# GD32H71x_72x register map
File version: 1.0
CPU: CM7 r1p2, little endian, MPU, FPU, 4 interrupt priority bits
Registers are 32-bit, read-write, reset 0x0 unless marked. A register's access mark holds for its fields unless they carry their own. Offsets are from the block's base; [hi:lo] are bit positions.

## PMU — Power management unit
Base 0x58005800
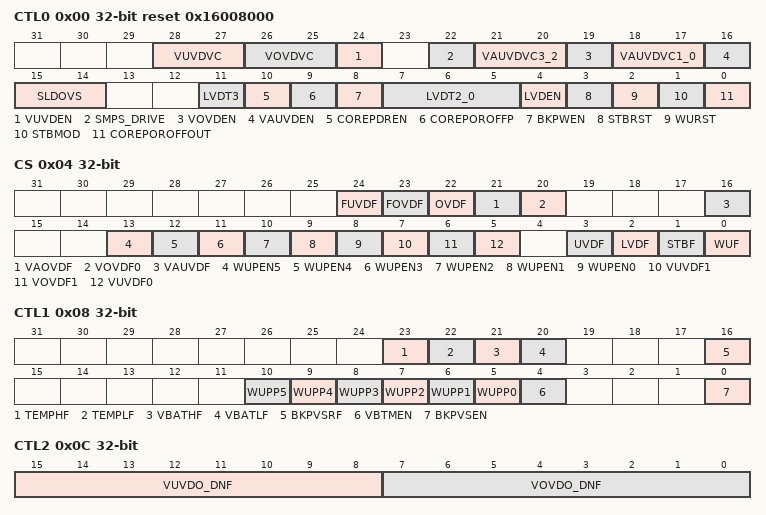
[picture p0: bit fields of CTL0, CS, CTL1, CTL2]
0x00 CTL0 reset 0x16008000 — Control register 0
  [28:27] VUVDVC — VCORE under voltage detector voltage level configure bits
  [26:25] VOVDVC — VCORE over voltage detector voltage level configure bits.
  [24] VUVDEN — VCORE under voltage detector enable
  [22] SMPS_DRIVE — SMPS_DRIVE drive capability selection
  [21:20] VAUVDVC3_2 — VDDA analog under voltage detector voltage level configure bits 2~3
  [19] VOVDEN — VCORE over voltage detector voltage level enable bit
  [18:17] VAUVDVC1_0 — VDDA analog under voltage detector voltage level configure bits 0~1
  [16] VAUVDEN — VDDA analog under voltage detector enable bit
  [15:14] SLDOVS — Deep-sleep mode voltage scaling selection
  [11] LVDT3 — VDD low voltage detector threshold bit 3
  [10] COREPDREN — CORE PDR circuit enable signal
  [9] COREPOROFFP — CORE POR OFF output polarity selection ( Standby mode output from PC7 )
  [8] BKPWEN — Backup domain write enable bit
  [7:5] LVDT2_0 — VDD low voltage detector threshold bits 0~2
  [4] LVDEN — Low voltage detector enable bit
  [3] STBRST — Standby flag reset bit
  [2] WURST — Wakeup flag reset bit
  [1] STBMOD — Standby Mode
  [0] COREPOROFFOUT — CORE POR OFF output is enabled
0x04 CS access per field — Control and status register
  [24] FUVDF ro — Flash LDO under voltage flag bit
  [23] FOVDF ro — Flash LDO over voltage flag bit
  [22] OVDF ro — VDD over voltage flag bit
  [21] VAOVDF ro — VDDA over voltage flag bit
  [20] VOVDF0 ro — Peripheral voltage on VCORE detector flag bit
  [16] VAUVDF ro — Analog under voltage detector output on VDDA
  [13] WUPEN5 rw — WKUP Pin5 (PC1) enable
  [12] WUPEN4 rw — WKUP pin4 (PC6) enable
  [11] WUPEN3 rw — WKUP pin3 (PC13) enable
  [10] WUPEN2 rw — WKUP pin2 (PB8) enable
  [9] WUPEN1 rw — WKUP pin1 (PA2) enable
  [8] WUPEN0 rw — WKUP pin0 (PA0) enable
  [7] VUVDF1 ro — VCORE under voltage detector flag bit after digital filter
  [6] VOVDF1 ro — VCORE over voltage detector flag bit after digital filter
  [5] VUVDF0 ro — VCORE under voltage detector flag bit
  [3] UVDF ro — Record the undervoltage reset of the VCORE
  [2] LVDF ro — Low voltage detector status flag
  [1] STBF ro — Standby flag
  [0] WUF ro — Wakeup Flag
0x08 CTL1 access per field — Control register 1
  [23] TEMPHF ro — Temperature level monitoring versus high threshold
  [22] TEMPLF ro — Temperature level monitoring versus low threshold
  [21] VBATHF ro — VBAT level monitoring versus high threshold
  [20] VBATLF ro — VBAT level monitoring versus low threshold
  [16] BKPVSRF ro — Backup voltage stabilizer ready flag
  [10] WUPP5 rw — WKUP Pin5(PC1) polarity
  [9] WUPP4 rw — WKUP Pin4(PC6) polarity
  [8] WUPP3 rw — WKUP Pin3(PC13) polarity
  [7] WUPP2 rw — WKUP Pin2(PB8) polarity
  [6] WUPP1 rw — WKUP Pin1(PA2) polarity
  [5] WUPP0 rw — WKUP Pin4(PA0) polarity
  [4] VBTMEN rw — VBAT and temperature monitoring enable.
  [0] BKPVSEN rw — Backup voltage stabilizer enable
0x0C CTL2 — Control register 2
  [15:8] VUVDO_DNF — VUVD analog output digital noise filter
  [7:0] VOVDO_DNF — VOVD analog output digital noise filter
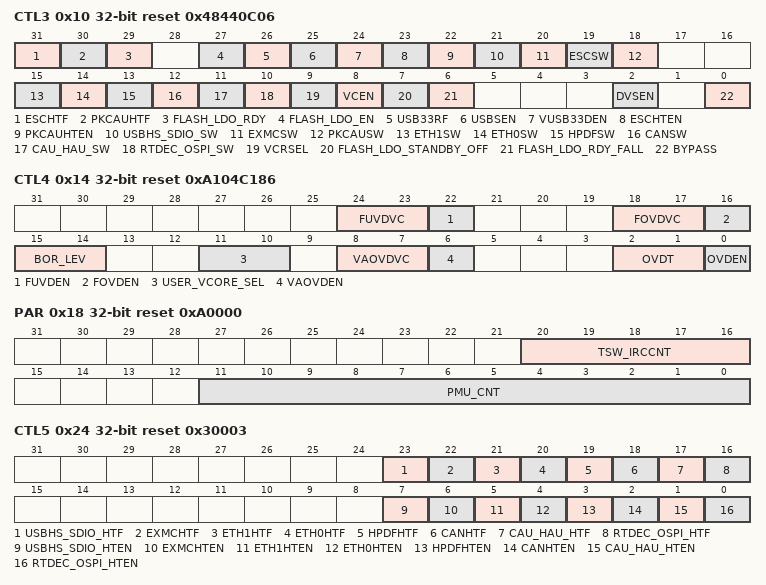
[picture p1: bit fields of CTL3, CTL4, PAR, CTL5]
0x10 CTL3 access per field reset 0x48440C06 — Control register 3
  [31] ESCHTF ro — ESC power switch ack flag.
  [30] PKCAUHTF ro — PKCAU power switch ack flag.
  [29] FLASH_LDO_RDY ro — The FLASH LDO voltage ready signal
  [27] FLASH_LDO_EN rw — FLASH LDO enable signal.
  [26] USB33RF ro — USB supply ready flag bit.
  [25] USBSEN rw — USB voltage stabilizer enable.
  [24] VUSB33DEN rw — VDD33USB voltage level detector enable bit.
  [23] ESCHTEN rw — ESC output isolation enable.
  [22] PKCAUHTEN rw — PKCAU output isolation enable.
  [21] USBHS_SDIO_SW rw — Powers off the USBHS and SDIO.
  [20] EXMCSW rw — Powers off the EXMC.
  [19] ESCSW rw — Powers off the ESC.
  [18] PKCAUSW rw — Powers off the PKCAU.
  [15] ETH1SW rw — Powers off the ETH1.
  [14] ETH0SW rw — Powers off the ETH0.
  [13] HPDFSW rw — Powers off the HPDF.
  [12] CANSW rw — Powers off the CAN.
  [11] CAU_HAU_SW rw — Powers off the CAU and HAU.
  [10] RTDEC_OSPI_SW rw — Powers off the RTDEC and OSPI.
  [9] VCRSEL rw — VBAT battery charging resistor selection.
  [8] VCEN rw — VBAT battery charging enable.
  [7] FLASH_LDO_STANDBY_OFF rw — Off the flash LDO in standby mode
  [6] FLASH_LDO_RDY_FALL rw — Flash LDO ready signal falling edge flag
  [2] DVSEN rw — Step-down voltage stabilizer enable bit.
  [0] BYPASS rw — Power management unit bypass control bit.
0x14 CTL4 reset 0xA104C186 — Control register 4
  [24:23] FUVDVC — FLASH LDO under voltage detector voltage level configure bits.
  [22] FUVDEN — FLASH LDO under voltage detector enable bit
  [18:17] FOVDVC — FLASH LDO over voltage detector voltage level configure bits.
  [16] FOVDEN — FLASH LDO over voltage detector enable bit
  [15:14] BOR_LEV — BOR (Brown-Out Reset) enable control and level selection
  [11:10] USER_VCORE_SEL — User VCORE voltage select
  [8:7] VAOVDVC — VDDA analog over voltage detector voltage level configure bits
  [6] VAOVDEN — VDDA over voltage detector enable bit
  [2:1] OVDT — VDD over voltage detector threshold
  [0] OVDEN — VDD over voltage detector enable bit
0x18 PAR reset 0xA0000 — Parameter register
  [20:16] TSW_IRCCNT — When enter Deep-sleep, switch to LPIRC4M / IRC64M (confirmed by DSPWUSSEL) clock. Wait the LPIRC4M / IRC64M (confirmed by DSPWUSSEL) counter and then set stop_state signal. The default is 10 clocks.
  [11:0] PMU_CNT — Exit Deep-sleep mode wait time count configure bits
0x24 CTL5 access per field reset 0x30003 — Control register 5
  [23] USBHS_SDIO_HTF ro — USBHS_SDIO power switch ack flag.
  [22] EXMCHTF ro — EXMC power switch ack flag.
  [21] ETH1HTF ro — ETH1 power switch ack flag.
  [20] ETH0HTF ro — ETH0 power switch ack flag.
  [19] HPDFHTF ro — HPDF power switch ack flag.
  [18] CANHTF ro — CAN power switch ack flag.
  [17] CAU_HAU_HTF ro — CAU_HAU power switch ack flag.
  [16] RTDEC_OSPI_HTF ro — RTDEC_OSPI power switch ack flag.
  [7] USBHS_SDIO_HTEN rw — USBHS and SDIO output isolation enable.
  [6] EXMCHTEN rw — EXMC output isolation enable.
  [5] ETH1HTEN rw — ETH1 output isolation enable.
  [4] ETH0HTEN rw — ETH0 output isolation enable.
  [3] HPDFHTEN rw — HPDF output isolation enable.
  [2] CANHTEN rw — CAN output isolation enable.
  [1] CAU_HAU_HTEN rw — CAU and HAU output isolation enable.
  [0] RTDEC_OSPI_HTEN rw — RTDEC and OSPI output isolation enable.
